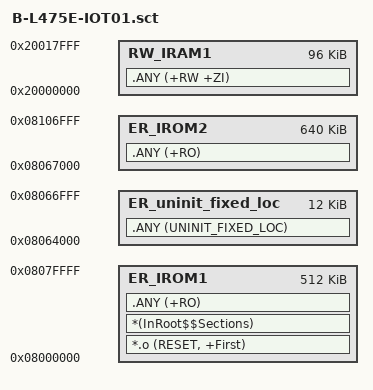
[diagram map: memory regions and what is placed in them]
; *************************************************************
; *** Scatter-Loading Description File                      ***
; *************************************************************

LR_IROM1 0x08000000 0x00080000  {    ; load region size_region
  ER_IROM1 0x08000000 0x00080000  {  ; load address = execution address
   *.o (RESET, +First)
   *(InRoot$$Sections)
   .ANY (+RO)
  }
  RW_IRAM1 0x20000000 0x00018000  {  ; RW data
   .ANY (+RW +ZI)
   }
  }
   
LR_uninit_fixed_loc 0x08064000 0x3000 {
  ER_uninit_fixed_loc 0x08064000 0x3000 {
    .ANY (UNINIT_FIXED_LOC)
  }
 }

LR_IROM2 0x08067000 0xA0000  {    ; load region size_region
  ER_IROM2 0x08067000 0xA0000  {  ; load address = execution address
   .ANY (+RO)
  } 
}
